VERSION ""

NS_ :

BS_:

BU_:

BO_ 2047 ReferenceSpeed: 8 Vector__XXX

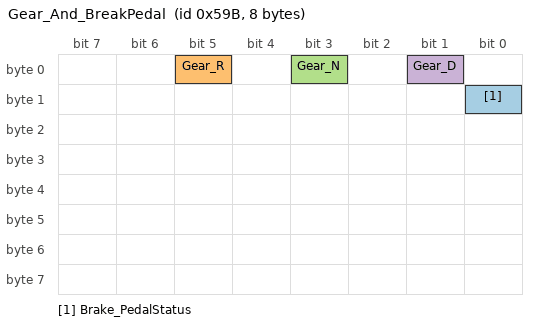
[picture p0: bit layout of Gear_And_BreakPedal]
BO_ 1435 Gear_And_BreakPedal: 8 Vector__XXX
 SG_ Brake_PedalStatus : 8|1@1+ (1,0) [0|0] "" Vector__XXX
 SG_ Gear_R : 5|1@1+ (1,0) [0|0] "" Vector__XXX
 SG_ Gear_N : 3|1@1+ (1,0) [0|0] "" Vector__XXX
 SG_ Gear_D : 1|1@1+ (1,0) [0|0] "" Vector__XXX

BO_ 1433 CurrentSpeed: 8 Vector__XXX
 SG_ Curr_Speed : 47|16@0- (0.01,0) [0|0] "" Vector__XXX

BA_DEF_  "BusType" STRING ;
BA_DEF_DEF_  "BusType" "";
BA_ "BusType" "CAN";
